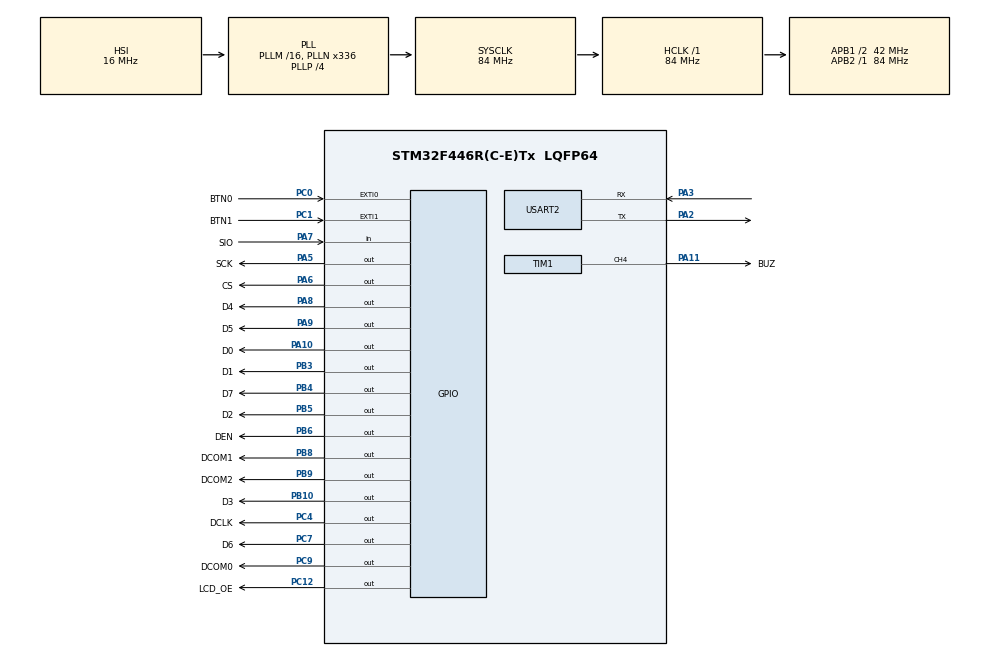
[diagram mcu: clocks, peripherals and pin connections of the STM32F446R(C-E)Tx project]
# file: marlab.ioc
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Mcu.Family=STM32F4
Mcu.Name=STM32F446R(C-E)Tx
Mcu.Package=LQFP64
NVIC.EXTI0_IRQn=true\:0\:0\:false\:false\:true
NVIC.EXTI1_IRQn=true\:0\:0\:false\:false\:true
NVIC.PriorityGroup=NVIC_PRIORITYGROUP_4
NVIC.TIM2_IRQn=true\:0\:0\:false\:false\:true
NVIC.TIM3_IRQn=true\:0\:0\:false\:false\:true
NVIC.TIM4_IRQn=true\:0\:0\:false\:false\:true
PA10.GPIO_Label=D0
PA10.Signal=GPIO_Output
PA11.GPIO_Label=BUZ
PA11.Signal=S_TIM1_CH4
PA2.Mode=Asynchronous
PA2.Signal=USART2_TX
PA3.Mode=Asynchronous
PA3.Signal=USART2_RX
PA5.GPIO_Label=SCK
PA5.Signal=GPIO_Output
PA6.GPIO_Label=CS
PA6.GPIO_Speed=GPIO_SPEED_FREQ_VERY_HIGH
PA6.Signal=GPIO_Output
PA7.GPIO_Label=SIO
PA7.Signal=GPIO_Input
PA8.GPIO_Label=D4
PA8.Signal=GPIO_Output
PA9.GPIO_Label=D5
PA9.Signal=GPIO_Output
PB10.GPIO_Label=D3
PB10.Signal=GPIO_Output
PB3.GPIO_Label=D1
PB3.Signal=GPIO_Output
PB4.GPIO_Label=D7
PB4.Signal=GPIO_Output
PB5.GPIO_Label=D2
PB5.Signal=GPIO_Output
PB6.GPIO_Label=DEN
PB6.Signal=GPIO_Output
PB8.GPIO_Label=DCOM1
PB8.Signal=GPIO_Output
PB9.GPIO_Label=DCOM2
PB9.Signal=GPIO_Output
PC0.GPIO_Label=BTN0
PC0.Signal=GPXTI0
PC1.GPIO_Label=BTN1
PC1.Signal=GPXTI1
PC12.GPIO_Label=LCD_OE
PC12.Signal=GPIO_Output
PC4.GPIO_Label=DCLK
PC4.Signal=GPIO_Output
PC7.GPIO_Label=D6
PC7.Signal=GPIO_Output
PC9.GPIO_Label=DCOM0
PC9.Signal=GPIO_Output
PH0-OSC_IN.Mode=HSE-External-Oscillator
PH0-OSC_IN.Signal=RCC_OSC_IN
PH1-OSC_OUT.Mode=HSE-External-Oscillator
PH1-OSC_OUT.Signal=RCC_OSC_OUT
ProjectManager.HeapSize=0x200
ProjectManager.StackSize=0x400
ProjectManager.TargetToolchain=SW4STM32
RCC.AHBFreq_Value=84000000
RCC.APB1CLKDivider=RCC_HCLK_DIV2
RCC.APB1Freq_Value=42000000
RCC.APB1TimFreq_Value=84000000
RCC.APB2Freq_Value=84000000
RCC.APB2TimFreq_Value=84000000
RCC.CortexFreq_Value=84000000
RCC.HCLKFreq_Value=84000000
RCC.HSE_VALUE=25000000
RCC.PLLN=336
RCC.PLLP=RCC_PLLP_DIV4
RCC.SYSCLKFreq_VALUE=84000000
RCC.SYSCLKSource=RCC_SYSCLKSOURCE_PLLCLK
RCC.USBFreq_Value=168000000
RCC.VCOOutputFreq_Value=336000000
SH.S_TIM1_CH4.0=TIM1_CH4,PWM Generation4 CH4
TIM1.Channel-PWM\ Generation4\ CH4=TIM_CHANNEL_4
TIM1.Period=9999
TIM1.Prescaler=83
TIM2.Period=20
TIM2.Prescaler=42000
TIM3.Period=2
TIM3.Prescaler=42000
TIM4.Period=2000
TIM4.Prescaler=42000
VP_TIM1_VS_ClockSourceINT.Mode=Internal
VP_TIM2_VS_ClockSourceINT.Mode=Internal
VP_TIM2_VS_no_output1.Mode=Output Compare1 No Output
VP_TIM3_VS_ClockSourceINT.Mode=Internal
VP_TIM3_VS_no_output1.Mode=Output Compare1 No Output
VP_TIM4_VS_no_output1.Mode=Output Compare1 No Output
board=marlab

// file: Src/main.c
/**
  ******************************************************************************
  * File Name          : main.c
  * Description        : Main program body
  ******************************************************************************
  *
  * COPYRIGHT(c) 2017 STMicroelectronics
  *
  * Redistribution and use in source and binary forms, with or without modification,
  * are permitted provided that the following conditions are met:
  *   1. Redistributions of source code must retain the above copyright notice,
  *      this list of conditions and the following disclaimer.
  *   2. Redistributions in binary form must reproduce the above copyright notice,
  *      this list of conditions and the following disclaimer in the documentation
  *      and/or other materials provided with the distribution.
  *   3. Neither the name of STMicroelectronics nor the names of its contributors
  *      may be used to endorse or promote products derived from this software
  *      without specific prior written permission.
  *
  * THIS SOFTWARE IS PROVIDED BY THE COPYRIGHT HOLDERS AND CONTRIBUTORS "AS IS"
  * AND ANY EXPRESS OR IMPLIED WARRANTIES, INCLUDING, BUT NOT LIMITED TO, THE
  * IMPLIED WARRANTIES OF MERCHANTABILITY AND FITNESS FOR A PARTICULAR PURPOSE ARE
  * DISCLAIMED. IN NO EVENT SHALL THE COPYRIGHT HOLDER OR CONTRIBUTORS BE LIABLE
  * FOR ANY DIRECT, INDIRECT, INCIDENTAL, SPECIAL, EXEMPLARY, OR CONSEQUENTIAL
  * DAMAGES (INCLUDING, BUT NOT LIMITED TO, PROCUREMENT OF SUBSTITUTE GOODS OR
  * SERVICES; LOSS OF USE, DATA, OR PROFITS; OR BUSINESS INTERRUPTION) HOWEVER
  * CAUSED AND ON ANY THEORY OF LIABILITY, WHETHER IN CONTRACT, STRICT LIABILITY,
  * OR TORT (INCLUDING NEGLIGENCE OR OTHERWISE) ARISING IN ANY WAY OUT OF THE USE
  * OF THIS SOFTWARE, EVEN IF ADVISED OF THE POSSIBILITY OF SUCH DAMAGE.
  *
  ******************************************************************************
  */
#include "main.h"
#include "stm32f4xx_hal.h"
#include "tim.h"
#include "usart.h"
#include "gpio.h"

/* USER CODE BEGIN Includes */
#include "display.h"
#include "buzzer.h"
#include "temp.h"
/* USER CODE END Includes */

/* USER CODE BEGIN PV */
/* Private variables ---------------------------------------------------------*/

/* USER CODE END PV */

void SystemClock_Config(void);
void Error_Handler(void);

/* USER CODE BEGIN PFP */
/* Private function prototypes -----------------------------------------------*/

/* USER CODE END PFP */

int main(void)
{

  /* MCU Configuration----------------------------------------------------------*/

  /* Reset of all peripherals, Initializes the Flash interface and the Systick. */
  HAL_Init();

  /* Configure the system clock */
  SystemClock_Config();

  /* Initialize all configured peripherals */
  MX_GPIO_Init();
  MX_USART2_UART_Init();
  MX_TIM1_Init();
  MX_TIM3_Init();
  MX_TIM2_Init();
  MX_TIM4_Init();

  /* USER CODE BEGIN 2 */
  // Timerek, rИszegysИgek indМtАsa
  HAL_Delay(500);
  while (!temp_valid());
  get_temp();

  display_start();
  display_enable();
  buzzer_start();
  HAL_TIM_Base_Start_IT(&htim2);
  HAL_TIM_Base_Start_IT(&htim4);
  HAL_GPIO_WritePin(CS_GPIO_Port, CS_Pin, GPIO_PIN_SET); // SPI CS fel
  /* USER CODE END 2 */

  /* Infinite loop */
  while (1)
  {

  }

}

/** System Clock Configuration
*/
void SystemClock_Config(void)
{

  RCC_OscInitTypeDef RCC_OscInitStruct;
  RCC_ClkInitTypeDef RCC_ClkInitStruct;

    /**Configure the main internal regulator output voltage
    */
  __HAL_RCC_PWR_CLK_ENABLE();

  __HAL_PWR_VOLTAGESCALING_CONFIG(PWR_REGULATOR_VOLTAGE_SCALE3);

    /**Initializes the CPU, AHB and APB busses clocks
    */
  RCC_OscInitStruct.OscillatorType = RCC_OSCILLATORTYPE_HSI;
  RCC_OscInitStruct.HSIState = RCC_HSI_ON;
  RCC_OscInitStruct.HSICalibrationValue = 16;
  RCC_OscInitStruct.PLL.PLLState = RCC_PLL_ON;
  RCC_OscInitStruct.PLL.PLLSource = RCC_PLLSOURCE_HSI;
  RCC_OscInitStruct.PLL.PLLM = 16;
  RCC_OscInitStruct.PLL.PLLN = 336;
  RCC_OscInitStruct.PLL.PLLP = RCC_PLLP_DIV4;
  RCC_OscInitStruct.PLL.PLLQ = 2;
  RCC_OscInitStruct.PLL.PLLR = 2;
  if (HAL_RCC_OscConfig(&RCC_OscInitStruct) != HAL_OK)
  {
    Error_Handler();
  }

    /**Initializes the CPU, AHB and APB busses clocks
    */
  RCC_ClkInitStruct.ClockType = RCC_CLOCKTYPE_HCLK|RCC_CLOCKTYPE_SYSCLK
                              |RCC_CLOCKTYPE_PCLK1|RCC_CLOCKTYPE_PCLK2;
  RCC_ClkInitStruct.SYSCLKSource = RCC_SYSCLKSOURCE_PLLCLK;
  RCC_ClkInitStruct.AHBCLKDivider = RCC_SYSCLK_DIV1;
  RCC_ClkInitStruct.APB1CLKDivider = RCC_HCLK_DIV2;
  RCC_ClkInitStruct.APB2CLKDivider = RCC_HCLK_DIV1;

  if (HAL_RCC_ClockConfig(&RCC_ClkInitStruct, FLASH_LATENCY_2) != HAL_OK)
  {
    Error_Handler();
  }

    /**Configure the Systick interrupt time
    */
  HAL_SYSTICK_Config(HAL_RCC_GetHCLKFreq()/1000);

    /**Configure the Systick
    */
  HAL_SYSTICK_CLKSourceConfig(SYSTICK_CLKSOURCE_HCLK);

  /* SysTick_IRQn interrupt configuration */
  HAL_NVIC_SetPriority(SysTick_IRQn, 0, 0);
}

void Error_Handler(void)
{
  while(1)
  {
  }
}

/************************ (C) COPYRIGHT STMicroelectronics *****END OF FILE****/
